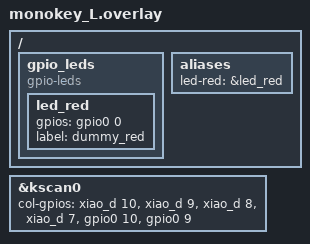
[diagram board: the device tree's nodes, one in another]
#include "monokey.dtsi"

&kscan0 {
    col-gpios
        = <&xiao_d 10 GPIO_ACTIVE_HIGH>
        , <&xiao_d 9 GPIO_ACTIVE_HIGH>
        , <&xiao_d 8 GPIO_ACTIVE_HIGH>
        , <&xiao_d 7 GPIO_ACTIVE_HIGH>
        , <&gpio0 10 GPIO_ACTIVE_HIGH>
        , <&gpio0 9 GPIO_ACTIVE_HIGH>
        ;
};

/ {
    gpio_leds: gpio_leds {
        compatible = "gpio-leds";

        led_red: led_red {
            gpios = <&gpio0 0 GPIO_ACTIVE_HIGH>;
            label = "dummy_red";
        };
    };

    aliases {
        led-red = &led_red;
    };
};
